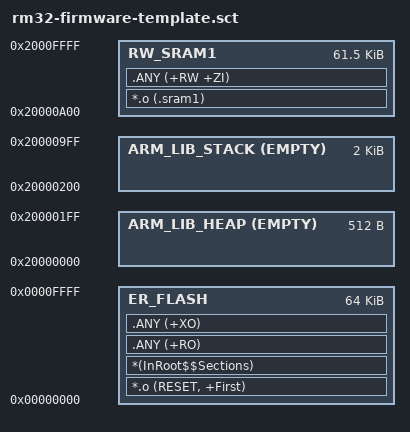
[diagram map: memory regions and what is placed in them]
#! armclang -E --target=arm-arm-none-eabi -mcpu=cortex-m0 -xc

#define __FLASH_MAIN_BANK_BASE    (0x00000000)
#define __FLASH_MAIN_BANK_SIZE    (0x00010000)
#define __SRAM1_BASE              (0x20000000)
#define __SRAM1_SIZE              (0x00010000)

#define __HEAP_BASE               (__SRAM1_BASE)
#define __HEAP_SIZE               (0x00000200)

#define __STACK_BASE              (__SRAM1_BASE + __HEAP_SIZE)
#define __STACK_SIZE              (0x00000800)

#define __USER_SRAM1_BASE         (__SRAM1_BASE + __HEAP_SIZE + __STACK_SIZE)
#define __USER_SRAM1_SIZE         (__SRAM1_SIZE - __HEAP_SIZE - __STACK_SIZE)

LR_FLASH __FLASH_MAIN_BANK_BASE __FLASH_MAIN_BANK_SIZE {
    ER_FLASH __FLASH_MAIN_BANK_BASE __FLASH_MAIN_BANK_SIZE {
        *.o (RESET, +First)
        *(InRoot$$Sections)
        .ANY (+RO)
        .ANY (+XO)
    }

    ARM_LIB_STACK __STACK_BASE ALIGN 8 EMPTY __STACK_SIZE {
    }

    ARM_LIB_HEAP __HEAP_BASE ALIGN 8 EMPTY __HEAP_SIZE {
    }

    RW_SRAM1 __USER_SRAM1_BASE __USER_SRAM1_SIZE {
        *.o (.sram1)
        .ANY (+RW +ZI)
    }
}
